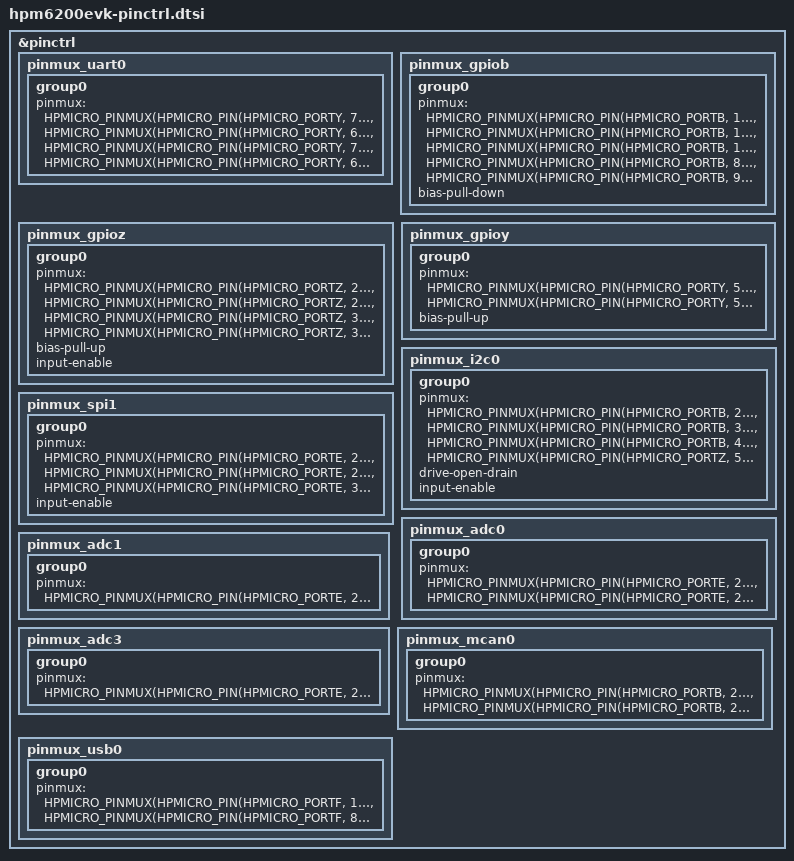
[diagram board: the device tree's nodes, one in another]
/*
 * Copyright 2025 HPMicro
 * SPDX-License-Identifier: Apache-2.0
 */

#include "dt-bindings/pinctrl/hpmicro-pinctrl-common.h"

&pinctrl {
	pinmux_uart0: pinmux_uart0 {
		group0 {
			pinmux = <HPMICRO_PINMUX(HPMICRO_PIN(HPMICRO_PORTY, 7), IOC_TYPE_IOC, 0, 2)>,
					 <HPMICRO_PINMUX(HPMICRO_PIN(HPMICRO_PORTY, 6), IOC_TYPE_IOC, 0, 2)>,
					 <HPMICRO_PINMUX(HPMICRO_PIN(HPMICRO_PORTY, 7), IOC_TYPE_PIOC, 0, 3)>,
					 <HPMICRO_PINMUX(HPMICRO_PIN(HPMICRO_PORTY, 6), IOC_TYPE_PIOC, 0, 3)>;
		};
	};

	pinmux_gpiob: pinmux_gpiob {
		group0 {
			pinmux = <HPMICRO_PINMUX(HPMICRO_PIN(HPMICRO_PORTB, 11), IOC_TYPE_IOC, 0, 0)>,
					 <HPMICRO_PINMUX(HPMICRO_PIN(HPMICRO_PORTB, 12), IOC_TYPE_IOC, 0, 0)>,
					 <HPMICRO_PINMUX(HPMICRO_PIN(HPMICRO_PORTB, 13), IOC_TYPE_IOC, 0, 0)>,
					 <HPMICRO_PINMUX(HPMICRO_PIN(HPMICRO_PORTB, 8), IOC_TYPE_IOC, 0, 0)>,
					 <HPMICRO_PINMUX(HPMICRO_PIN(HPMICRO_PORTB, 9), IOC_TYPE_IOC, 0, 0)>;
			bias-pull-down;
		};
	};

	pinmux_gpioz: pinmux_gpioz {
		group0 {
			pinmux = <HPMICRO_PINMUX(HPMICRO_PIN(HPMICRO_PORTZ, 2), IOC_TYPE_IOC, 0, 0)>,
					 <HPMICRO_PINMUX(HPMICRO_PIN(HPMICRO_PORTZ, 2), IOC_TYPE_BIOC, 0, 3)>,
					 <HPMICRO_PINMUX(HPMICRO_PIN(HPMICRO_PORTZ, 3), IOC_TYPE_IOC, 0, 0)>,
					 <HPMICRO_PINMUX(HPMICRO_PIN(HPMICRO_PORTZ, 3), IOC_TYPE_BIOC, 0, 3)>;
			bias-pull-up;
			input-enable;
		};
	};

	pinmux_gpioy: pinmux_gpioy {
		group0 {
			pinmux = <HPMICRO_PINMUX(HPMICRO_PIN(HPMICRO_PORTY, 5), IOC_TYPE_IOC, 0, 0)>,
					 <HPMICRO_PINMUX(HPMICRO_PIN(HPMICRO_PORTY, 5), IOC_TYPE_BIOC, 0, 3)>;
			bias-pull-up;
		};
	};

	pinmux_i2c0: pinmux_i2c0 {
		group0 {
			pinmux = <HPMICRO_PINMUX(HPMICRO_PIN(HPMICRO_PORTB, 2), IOC_TYPE_IOC, 0, 5)>,
					 <HPMICRO_PINMUX(HPMICRO_PIN(HPMICRO_PORTB, 3), IOC_TYPE_IOC, 0, 5)>,
					 <HPMICRO_PINMUX(HPMICRO_PIN(HPMICRO_PORTB, 4), IOC_TYPE_BIOC, 0, 5)>,
					 <HPMICRO_PINMUX(HPMICRO_PIN(HPMICRO_PORTZ, 5), IOC_TYPE_BIOC, 0, 5)>;
					 drive-open-drain;
					 input-enable;
		};
	};

	pinmux_spi1: pinmux_spi1 {
		group0 {
			pinmux = <HPMICRO_PINMUX(HPMICRO_PIN(HPMICRO_PORTE, 27), IOC_TYPE_IOC, 0, 5)>,
					 <HPMICRO_PINMUX(HPMICRO_PIN(HPMICRO_PORTE, 28), IOC_TYPE_IOC, 0, 5)>,
					 <HPMICRO_PINMUX(HPMICRO_PIN(HPMICRO_PORTE, 30), IOC_TYPE_IOC, 0, 5)>;
					 input-enable;
		};
	};

	pinmux_adc0: pinmux_adc0 {
		group0 {
			pinmux = <HPMICRO_PINMUX(HPMICRO_PIN(HPMICRO_PORTE, 24), IOC_TYPE_IOC, 1, 0)>,
					<HPMICRO_PINMUX(HPMICRO_PIN(HPMICRO_PORTE, 25), IOC_TYPE_IOC, 1, 0)>;
		};
	};

	pinmux_adc1: pinmux_adc1 {
		group0 {
			pinmux = <HPMICRO_PINMUX(HPMICRO_PIN(HPMICRO_PORTE, 21), IOC_TYPE_IOC, 1, 0)>;
		};
	};

	pinmux_adc3: pinmux_adc3 {
		group0 {
			pinmux = <HPMICRO_PINMUX(HPMICRO_PIN(HPMICRO_PORTE, 29), IOC_TYPE_IOC, 1, 0)>;
		};
	};

	pinmux_mcan0: pinmux_mcan0 {
		group0 {
			pinmux = <HPMICRO_PINMUX(HPMICRO_PIN(HPMICRO_PORTB, 20), IOC_TYPE_IOC, 0, 7)>,
					<HPMICRO_PINMUX(HPMICRO_PIN(HPMICRO_PORTB, 21), IOC_TYPE_IOC, 0, 7)>;
		};
	};

	pinmux_usb0: pinmux_usb0 {
		group0 {
			pinmux = <HPMICRO_PINMUX(HPMICRO_PIN(HPMICRO_PORTF, 10), IOC_TYPE_IOC, 0, 24)>,
					 <HPMICRO_PINMUX(HPMICRO_PIN(HPMICRO_PORTF,  8), IOC_TYPE_IOC, 0, 24)>;
		};
	};
};
